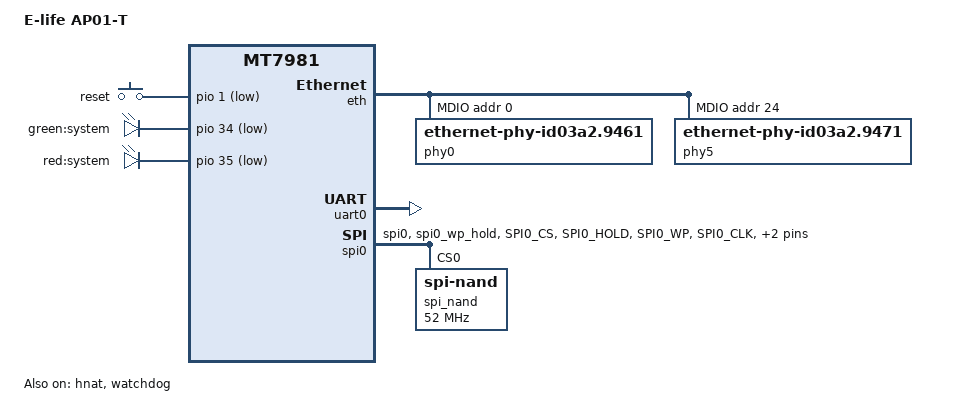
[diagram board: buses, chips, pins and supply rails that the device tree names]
// SPDX-License-Identifier: GPL-2.0-or-later OR MIT
/dts-v1/;

#include "mt7981.dtsi"

/ {
	model = "E-life AP01-T";
	compatible = "e-life,ap01-t", "mediatek,mt7981";

	aliases {
		led-boot = &led_system_red;
		led-failsafe = &led_system_red;
		led-running = &led_system_green;
		led-upgrade = &led_system_green;
	};

	chosen {
		bootargs = "console=ttyS0,115200n1 loglevel=8 \
			    earlycon=uart8250,mmio32,0x11002000";
	};

	gpio-keys {
		compatible = "gpio-keys";

		reset {
			label = "reset";
			linux,code = <KEY_RESTART>;
			gpios = <&pio 1 GPIO_ACTIVE_LOW>;
		};
	};

	leds {
		compatible = "gpio-leds";

		led_system_green: system_green {
			label = "green:system";
			gpios = <&pio 34 GPIO_ACTIVE_LOW>;
		};

		led_system_red: system_red {
			label = "red:system";
			gpios = <&pio 35 GPIO_ACTIVE_LOW>;
		};
	};

	nmbm_spim_nand {
		compatible = "generic,nmbm";
		#address-cells = <1>;
		#size-cells = <1>;

		lower-mtd-device = <&spi_nand>;
		max-reserved-blocks = <32>;
		forced-create;

		partitions {
			compatible = "fixed-partitions";
			#address-cells = <1>;
			#size-cells = <1>;

			partition@0 {
				label = "BL2";
				reg = <0x0000000 0x0100000>;
				read-only;
			};

			partition@100000 {
				label = "u-boot-env";
				reg = <0x0100000 0x0080000>;
			};

			partition@180000 {
				label = "Factory";
				reg = <0x0180000 0x0200000>;
				read-only;
			};

			partition@380000 {
				label = "FIP";
				reg = <0x0380000 0x0200000>;
				read-only;
			};

			partition@580000 {
				label = "ubi";
				reg = <0x0580000 0x7000000>;
			};
		};
	};
};

&eth {
	status = "okay";

	gmac0: mac@0 {
		compatible = "mediatek,eth-mac";
		reg = <0>;
		phy-mode = "sgmii";
		phy-handle = <&phy5>;
	};

	gmac1: mac@1 {
		compatible = "mediatek,eth-mac";
		reg = <1>;
		phy-mode = "gmii";
		phy-handle = <&phy0>;
	};

	mdio: mdio-bus {
		#address-cells = <1>;
		#size-cells = <0>;

		phy0: phy@0 {
			compatible = "ethernet-phy-id03a2.9461";
			reg = <0>;
		    phy-mode = "gmii";
			nvmem-cells = <&phy_calibration>;
			nvmem-cell-names = "phy-cal-data";
		};

		phy5: phy@5 {
			compatible = "ethernet-phy-id03a2.9471";
			reg = <24>;
			phy-mode = "sgmii";
		};
	};
};

&hnat {
	mtketh-wan = "eth0";
	mtketh-lan = "eth1";
	mtketh-max-gmac = <2>;
	status = "okay";
};

&uart0 {
        status = "okay";
};

&watchdog {
        status = "okay";
};
  
&spi0 {
        pinctrl-names = "default";
        pinctrl-0 = <&spi0_flash_pins>;
        status = "okay";

        spi_nand: spi_nand@0 {
                #address-cells = <1>;
                #size-cells = <1>;
                compatible = "spi-nand";
                reg = <0>;
                spi-max-frequency = <52000000>;
                spi-tx-bus-width = <4>;
                spi-rx-bus-width = <4>;
                spi-cal-enable;
                spi-cal-mode = "read-data";
                spi-cal-datalen = <7>;
                spi-cal-data = /bits/ 8 <0x53 0x50 0x49 0x4E 0x41 0x4E 0x44>; /* 'SPINAND' */
                spi-cal-addrlen = <5>;
                spi-cal-addr = /bits/ 32 <0x0 0x0 0x0 0x0 0x0>;
        };
};

&pio {
	spi0_flash_pins: spi0-pins {
		mux {
			function = "spi";
			groups = "spi0", "spi0_wp_hold";
		};

		conf-pu {
			pins = "SPI0_CS", "SPI0_HOLD", "SPI0_WP";
			drive-strength = <MTK_DRIVE_8mA>;
			bias-pull-up = <MTK_PUPD_SET_R1R0_11>;
		};

		conf-pd {
			pins = "SPI0_CLK", "SPI0_MOSI", "SPI0_MISO";
			drive-strength = <MTK_DRIVE_8mA>;
			bias-pull-down = <MTK_PUPD_SET_R1R0_11>;
		};
	};
};
